AUTOSAR XML (schema 00050)
package /MICROSAR/vRoE/Cdd_swc/DataTypes
  5 x impl type:
    vRoE_MessageType: category=ARRAY, sw-calibration-access=READ-ONLY
      element vRoE_MessageTypeElement: array-size=8, array-size-semantics=FIXED-SIZE, implementation-data-type=uint8
    vRoE_ActivationStateType: compu {0=VROE_STATE_ENABLED, 1=VROE_STATE_DISABLED}, range raw 0..1, implementation-data-type=uint8
    vRoE_ActivationStateArrayType: category=ARRAY, sw-calibration-access=READ-ONLY
      element vRoE_ActivationStateArrayTypeElement: array-size=1, array-size-semantics=FIXED-SIZE, implementation-data-type=vRoE_ActivationStateType
    vRoE_OpStatusType: compu {0=VROE_INITIAL, 1=VROE_PENDING, 2=VROE_CANCEL, 3=VROE_FORCE_RCRRP_OK, 64=VROE_FORCE_RCRRP_NOT_OK}, range raw 0..64, implementation-data-type=uint8
    vRoE_NegativeResponseCodeType: compu {34=VROE_E_CONDITIONSNOTCORRECT, 49=VROE_E_REQUESTOUTOFRANGE}, range raw 0..49, implementation-data-type=uint8
package /MICROSAR/vRoE/Cdd_swc/Interfaces
  sender receiver interface RoEMessageSRI: is-service=true, service-kind=VENDOR-SPECIFIC
    data Data: type=vRoE_MessageType
  client server interface RoEActivationCSI: is-service=true, service-kind=VENDOR-SPECIFIC
    operation WriteData: possible-error=[E_NOT_OK, DCM_E_PENDING]
      arg data: type=vRoE_ActivationStateArrayType, direction=IN
      arg opStatus: type=vRoE_OpStatusType, direction=IN
      arg errorCode: type=vRoE_NegativeResponseCodeType, direction=OUT
    operation ReadData: possible-error=[E_NOT_OK, DCM_E_PENDING]
      arg opStatus: type=vRoE_OpStatusType, direction=IN
      arg data: type=vRoE_ActivationStateArrayType, direction=OUT
    error E_NOT_OK: error-code=1
    error DCM_E_PENDING: error-code=10
package /MICROSAR/vRoE/Cdd_swc/ComponentTypes
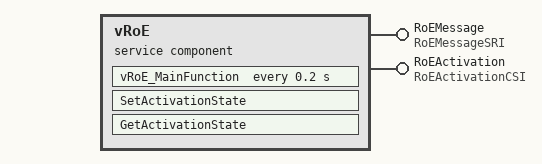
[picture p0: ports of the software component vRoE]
  service sw component type vRoE: category=SERVICE_COMPONENT
    provide port RoEMessage: provided-interface=RoEMessageSRI
    provide port RoEActivation: provided-interface=RoEActivationCSI
    behavior vRoEInternalBehavior: handle-termination-and-restart=NO-SUPPORT
      timing event Timer_vRoE_MainFunction: start-on-event=vRoE_MainFunction, period=0.2
      operation invoked event OpEventSetActivationState_WriteData_RoEActivation: start-on-event=SetActivationState, operation=RoEActivation.WriteData
      operation invoked event OpEventGetActivationState_ReadData_RoEActivation: start-on-event=GetActivationState, operation=RoEActivation.ReadData
      port-api-options:
        enable-take-address=true, indirect-api=false, port=RoEMessage
        enable-take-address=true, indirect-api=false, port=RoEActivation
      runnable vRoE_MainFunction
        data-send-points:
          access DataSendPointvRoE_MainFunction_RoEMessage_Data: accessed-variable=RoEMessage.Data
      runnable SetActivationState: can-be-invoked-concurrently=true, symbol=vRoE_SetActivationState
      runnable GetActivationState: can-be-invoked-concurrently=true, symbol=vRoE_GetActivationState
  swc implementation vRoEImplementation: programming-language=C, behavior=vRoEInternalBehavior
    resource consumption vRoEResourceConsumption
      5 x memory section:
        vRoE_START_SEC_CODE: sw-addrmethod=CODE, symbol=CODE
        vRoE_START_SEC_CONST_UNSPECIFIED: alignment=UNSPECIFIED, sw-addrmethod=CONST, symbol=CONST_UNSPECIFIED
        vRoE_START_SEC_VAR_NOINIT_UNSPECIFIED: alignment=UNSPECIFIED, sw-addrmethod=VAR_NO_INIT, symbol=VAR_NOINIT_UNSPECIFIED
        vRoE_START_SEC_VAR_INIT_UNSPECIFIED: alignment=UNSPECIFIED, sw-addrmethod=VAR_INIT, symbol=VAR_INIT_UNSPECIFIED
        vRoE_START_SEC_VAR_ZERO_INIT_UNSPECIFIED: alignment=UNSPECIFIED, sw-addrmethod=VAR_CLEARED, symbol=VAR_ZERO_INIT_UNSPECIFIED
